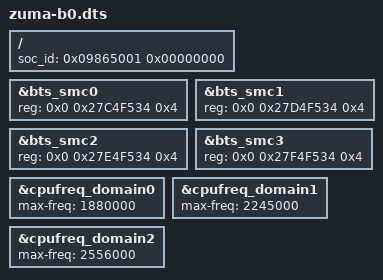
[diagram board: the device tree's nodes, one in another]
// SPDX-License-Identifier: GPL-2.0-only
/*
 * Copyright 2021 Google LLC.
 *
 */

/dts-v1/;
/ {
	/* soc revision info */
	soc_id = <0x09865001 0x00000000>;
};

#include "zuma.dtsi"

&bts_smc0 {
	reg = <0x0 0x27C4F534 0x4>;
};

&bts_smc1 {
	reg = <0x0 0x27D4F534 0x4>;
};

&bts_smc2 {
	reg = <0x0 0x27E4F534 0x4>;
};

&bts_smc3 {
	reg = <0x0 0x27F4F534 0x4>;
};

&cpufreq_domain0 {
	max-freq = <1880000>;
};
&cpufreq_domain1 {
	max-freq = <2245000>;
};
&cpufreq_domain2 {
	max-freq = <2556000>;
};
